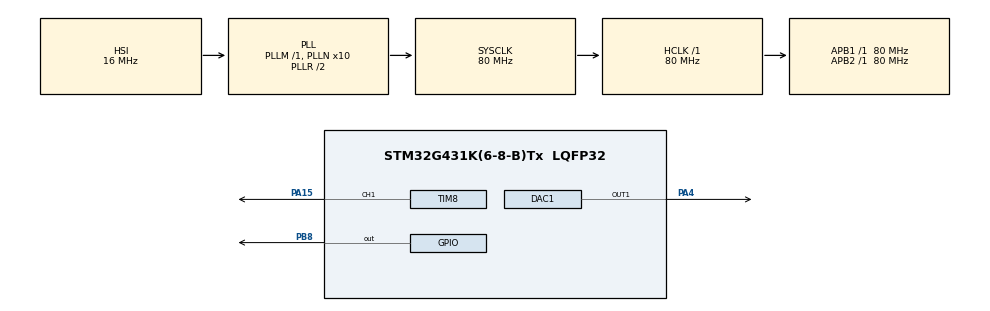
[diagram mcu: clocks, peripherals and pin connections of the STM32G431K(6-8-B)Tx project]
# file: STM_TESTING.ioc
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DAC1.DAC_SampleAndHold-DAC_OUT1=DAC_SAMPLEANDHOLD_DISABLE
DAC1.DAC_Trigger_OUT1-DAC_OUT1=DAC_TRIGGER_T2_TRGO
Dma.DAC1_CH1.0.Direction=DMA_MEMORY_TO_PERIPH
Dma.DAC1_CH1.0.EventEnable=DISABLE
Dma.DAC1_CH1.0.Instance=DMA1_Channel2
Dma.DAC1_CH1.0.MemDataAlignment=DMA_MDATAALIGN_HALFWORD
Dma.DAC1_CH1.0.MemInc=DMA_MINC_ENABLE
Dma.DAC1_CH1.0.Mode=DMA_CIRCULAR
Dma.DAC1_CH1.0.PeriphDataAlignment=DMA_PDATAALIGN_WORD
Dma.DAC1_CH1.0.PeriphInc=DMA_PINC_DISABLE
Dma.DAC1_CH1.0.Polarity=HAL_DMAMUX_REQ_GEN_RISING
Dma.DAC1_CH1.0.Priority=DMA_PRIORITY_HIGH
Dma.DAC1_CH1.0.RequestNumber=1
Dma.DAC1_CH1.0.SignalID=NONE
Dma.DAC1_CH1.0.SyncEnable=DISABLE
Dma.DAC1_CH1.0.SyncPolarity=HAL_DMAMUX_SYNC_NO_EVENT
Dma.DAC1_CH1.0.SyncRequestNumber=1
Dma.DAC1_CH1.0.SyncSignalID=NONE
Dma.Request0=DAC1_CH1
Mcu.Family=STM32G4
Mcu.Name=STM32G431K(6-8-B)Tx
Mcu.Package=LQFP32
NUCLEO-G431KB.LD2=true
NUCLEO-G431KB.VCP=true
NVIC.DMA1_Channel2_IRQn=true\:0\:0\:false\:false\:true\:false\:true\:true
NVIC.PriorityGroup=NVIC_PRIORITYGROUP_4
NVIC.TIM2_IRQn=true\:0\:0\:false\:false\:true\:true\:true\:true
NVIC.TIM8_UP_IRQn=true\:0\:0\:false\:false\:true\:true\:true\:true
PA13.GPIO_Label=T_SWDIO
PA13.Signal=SYS_JTMS-SWDIO
PA14.GPIO_Label=T_SWCLK
PA14.Signal=SYS_JTCK-SWCLK
PA15.Signal=S_TIM8_CH1
PA2.Signal=USART2_TX
PA3.Signal=USART2_RX
PA4.Signal=COMP_DAC11_group
PB3.GPIO_Label=T_SWO
PB3.Signal=SYS_JTDO-SWO
PB8-BOOT0.Signal=GPIO_Output
ProjectManager.HeapSize=0x200
ProjectManager.StackSize=0x400
ProjectManager.TargetToolchain=CMake
RCC.ADC12Freq_Value=80000000
RCC.AHBFreq_Value=80000000
RCC.APB1Freq_Value=80000000
RCC.APB1TimFreq_Value=80000000
RCC.APB2Freq_Value=80000000
RCC.APB2TimFreq_Value=80000000
RCC.CortexFreq_Value=80000000
RCC.EXTERNAL_CLOCK_VALUE=12288000
RCC.HCLKFreq_Value=80000000
RCC.HSE_VALUE=8000000
RCC.HSI48_VALUE=48000000
RCC.HSI_VALUE=16000000
RCC.LSE_VALUE=32768
RCC.PLLN=10
RCC.SYSCLKFreq_VALUE=80000000
RCC.SYSCLKSource=RCC_SYSCLKSOURCE_PLLCLK
RCC.USBFreq_Value=80000000
RCC.VCOOutputFreq_Value=160000000
SH.COMP_DAC11_group.0=DAC1_OUT1,DAC_OUT1
SH.S_TIM8_CH1.0=TIM8_CH1,PWM Generation1 CH1
TIM2.PeriodNoDither=9
TIM2.Prescaler=7999
TIM2.TIM_MasterOutputTrigger=TIM_TRGO_UPDATE
TIM8.Channel-PWM\ Generation1\ CH1=TIM_CHANNEL_1
TIM8.PeriodNoDither=9999
TIM8.Prescaler=7999
TIM8.PulseNoDither_1=10000
TIM8.RepetitionCounter=0
TIM8.TIM_MasterOutputTrigger=TIM_TRGO_OC1REF
VP_NUCLEO-G431KB_VS_BSP_COMMON.Mode=COMMON
VP_SYS_VS_DBSignals.Mode=DisableDeadBatterySignals
VP_TIM2_VS_ClockSourceINT.Mode=Internal
VP_TIM2_VS_ClockSourceITR.Mode=TriggerSource_ITR5
VP_TIM2_VS_ControllerModeGated.Mode=Gated Mode
VP_TIM8_VS_ClockSourceINT.Mode=Internal
board=NUCLEO-G431KB

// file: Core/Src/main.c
/* USER CODE BEGIN Header */
/**
 ******************************************************************************
 * @file           : main.c
 * @brief          : Main program body
 ******************************************************************************
 * @attention
 *
 * Copyright (c) 2025 STMicroelectronics.
 * All rights reserved.
 *
 * This software is licensed under terms that can be found in the LICENSE file
 * in the root directory of this software component.
 * If no LICENSE file comes with this software, it is provided AS-IS.
 *
 ******************************************************************************
 */
/* USER CODE END Header */
#include "main.h"

/* USER CODE BEGIN Includes */

#include <math.h>
#include <stdint.h>

/* USER CODE END Includes */

/* USER CODE BEGIN PD */

#define pi 3.14159265358979323846
#define MAX_SAMPLES_21k 48
#define MAX_SAMPLES_22k 45
#define BITSTREAM_LENGTH (32 * 8)

#define NUM_PERIODS_21k 30
#define NUM_PERIODS_22k 32

/* USER CODE END PD */

COM_InitTypeDef BspCOMInit;

DAC_HandleTypeDef hdac1;
DMA_HandleTypeDef hdma_dac1_ch1;

TIM_HandleTypeDef htim2;
TIM_HandleTypeDef htim8;

/* USER CODE BEGIN PV */

uint16_t sine_val_21k[MAX_SAMPLES_21k];
uint16_t sine_val_22k[MAX_SAMPLES_22k];

uint16_t bitstream[BITSTREAM_LENGTH];

static uint32_t current_period = 0;
static uint32_t current_bit = 0; // 0: 21kHz, 1: 22kHz
static uint32_t current_idx = 0; // Current index of the bitstream

/* USER CODE END PV */

void SystemClock_Config(void);
static void MX_GPIO_Init(void);
static void MX_DMA_Init(void);
static void MX_TIM2_Init(void);
static void MX_DAC1_Init(void);
static void MX_TIM8_Init(void);

/* USER CODE BEGIN 0 */

void make_random_bitstream(void) {
  for (int i = 0; i < BITSTREAM_LENGTH; i++) {
    bitstream[i] = rand() & 1; // Random bit (0 or 1)
  }
}

void make_bitstream_from_string(const char *str) {
  int bit_idx = 0;
  for (int i = 0; str[i] != '\0' && bit_idx < BITSTREAM_LENGTH; i++) {
    for (int b = 0; b < 8 && bit_idx < BITSTREAM_LENGTH; b++) {
      bitstream[bit_idx++] = (str[i] >> b) & 1;
    }
  }
  // Fill remaining bits with 0 if string is shorter than BITSTREAM_LENGTH
  while (bit_idx < BITSTREAM_LENGTH) {
    bitstream[bit_idx++] = 0;
  }
}

void get_sineval_21k(void) {
  for (int i = 0; i < MAX_SAMPLES_21k; i++) {
    sine_val_21k[i] = (uint16_t)((4095.0 / 2.0) *
                                 (1.0 + sinf(2.0 * pi * i / MAX_SAMPLES_21k)));
  }
}

void get_sineval_22k(void) {
  for (int i = 0; i < MAX_SAMPLES_22k; i++) {
    sine_val_22k[i] = (uint16_t)((4095.0 / 2.0) *
                                 (1.0 + sinf(2.0 * pi * i / MAX_SAMPLES_22k)));
  }
}

void HAL_TIM_PeriodElapsedCallback(TIM_HandleTypeDef *htim) {
  if (htim->Instance == TIM8) {
  }

  if (htim->Instance == TIM2) {
  }
}

void HAL_DAC_ConvCpltCallbackCh1(DAC_HandleTypeDef *hdac) {
  HAL_GPIO_TogglePin(GPIOA, GPIO_PIN_5);

  current_period++;

  if ((current_bit == 0 && current_period >= NUM_PERIODS_21k) ||
      (current_bit == 1 && current_period >= NUM_PERIODS_22k)) {
    current_idx = (current_idx + 1) % BITSTREAM_LENGTH;
    current_period = 0;
    uint32_t next_bit = bitstream[current_idx];

    if (next_bit != current_bit) {
      HAL_DAC_Stop_DMA(&hdac1, DAC_CHANNEL_1);

      if (next_bit == 1) {
        HAL_DAC_Start_DMA(&hdac1, DAC_CHANNEL_1, (uint32_t *)sine_val_22k,
                          MAX_SAMPLES_22k, DAC_ALIGN_12B_R);
      } else {
        HAL_DAC_Start_DMA(&hdac1, DAC_CHANNEL_1, (uint32_t *)sine_val_21k,
                          MAX_SAMPLES_21k, DAC_ALIGN_12B_R);
      }
      current_bit = next_bit;
    }
  }
}

void HAL_DAC_ConvHalfCpltCallbackCh1(DAC_HandleTypeDef *hdac) {
  // Called halfway through buffer
}

/* USER CODE END 0 */

int main(void) {

  /* MCU Configuration--------------------------------------------------------*/

  /* Reset of all peripherals, Initializes the Flash interface and the Systick.
   */
  HAL_Init();

  /* Configure the system clock */
  SystemClock_Config();

  /* Initialize all configured peripherals */
  MX_GPIO_Init();
  MX_DMA_Init();
  MX_TIM2_Init();
  MX_DAC1_Init();
  MX_TIM8_Init();

  /* Initialize leds */
  BSP_LED_Init(LED_GREEN);

  /* Initialize COM1 port (115200, 8 bits (7-bit data + 1 stop bit), no parity
   */
  BspCOMInit.BaudRate = 115200;
  BspCOMInit.WordLength = COM_WORDLENGTH_8B;
  BspCOMInit.StopBits = COM_STOPBITS_1;
  BspCOMInit.Parity = COM_PARITY_NONE;
  BspCOMInit.HwFlowCtl = COM_HWCONTROL_NONE;
  if (BSP_COM_Init(COM1, &BspCOMInit) != BSP_ERROR_NONE) {
    Error_Handler();
  }

  /* Infinite loop */
  /* USER CODE BEGIN WHILE */

  //-------------------------------------------------------------------------------------------//
  // Create a bistream from a string
  //-------------------------------------------------------------------------------------------//

  const char *input_string = "Hello"; // Example input string
  make_bitstream_from_string(input_string);
  // make_random_bitstream(); // or fill bitstream[] your way

  //-------------------------------------------------------------------------------------------//
  // Generate the sine wave lookup table
  //-------------------------------------------------------------------------------------------//

  get_sineval_21k();
  get_sineval_22k();

  //-------------------------------------------------------------------------------------------//
  // Generate the sine wave lookup table
  //-------------------------------------------------------------------------------------------//

  HAL_DAC_Start_DMA(&hdac1, DAC_CHANNEL_1, (uint32_t *)sine_val_21k,
                    MAX_SAMPLES_21k, DAC_ALIGN_12B_R);

  //-------------------------------------------------------------------------------------------//
  // STARTING TIMERS AND INTERRUPTS
  //-------------------------------------------------------------------------------------------//

  HAL_TIM_Base_Start_IT(&htim8); // enable update interrupt
  HAL_TIM_PWM_Start(&htim8, TIM_CHANNEL_1);

  // Start TIM2 (sample clock, gated by TIM8)
  HAL_TIM_Base_Start_IT(&htim2);

  //-------------------------------------------------------------------------------------------//

  while (1) {
    /* USER CODE END WHILE */

  }
}

void SystemClock_Config(void) {
  RCC_OscInitTypeDef RCC_OscInitStruct = {0};
  RCC_ClkInitTypeDef RCC_ClkInitStruct = {0};

  /** Configure the main internal regulator output voltage
   */
  HAL_PWREx_ControlVoltageScaling(PWR_REGULATOR_VOLTAGE_SCALE1);

  /** Initializes the RCC Oscillators according to the specified parameters
   * in the RCC_OscInitTypeDef structure.
   */
  RCC_OscInitStruct.OscillatorType = RCC_OSCILLATORTYPE_HSI;
  RCC_OscInitStruct.HSIState = RCC_HSI_ON;
  RCC_OscInitStruct.HSICalibrationValue = RCC_HSICALIBRATION_DEFAULT;
  RCC_OscInitStruct.PLL.PLLState = RCC_PLL_ON;
  RCC_OscInitStruct.PLL.PLLSource = RCC_PLLSOURCE_HSI;
  RCC_OscInitStruct.PLL.PLLM = RCC_PLLM_DIV1;
  RCC_OscInitStruct.PLL.PLLN = 10;
  RCC_OscInitStruct.PLL.PLLP = RCC_PLLP_DIV2;
  RCC_OscInitStruct.PLL.PLLQ = RCC_PLLQ_DIV2;
  RCC_OscInitStruct.PLL.PLLR = RCC_PLLR_DIV2;
  if (HAL_RCC_OscConfig(&RCC_OscInitStruct) != HAL_OK) {
    Error_Handler();
  }

  /** Initializes the CPU, AHB and APB buses clocks
   */
  RCC_ClkInitStruct.ClockType = RCC_CLOCKTYPE_HCLK | RCC_CLOCKTYPE_SYSCLK |
                                RCC_CLOCKTYPE_PCLK1 | RCC_CLOCKTYPE_PCLK2;
  RCC_ClkInitStruct.SYSCLKSource = RCC_SYSCLKSOURCE_PLLCLK;
  RCC_ClkInitStruct.AHBCLKDivider = RCC_SYSCLK_DIV1;
  RCC_ClkInitStruct.APB1CLKDivider = RCC_HCLK_DIV1;
  RCC_ClkInitStruct.APB2CLKDivider = RCC_HCLK_DIV1;

  if (HAL_RCC_ClockConfig(&RCC_ClkInitStruct, FLASH_LATENCY_2) != HAL_OK) {
    Error_Handler();
  }
}

static void MX_DAC1_Init(void) {

  DAC_ChannelConfTypeDef sConfig = {0};

  /** DAC Initialization
   */
  hdac1.Instance = DAC1;
  if (HAL_DAC_Init(&hdac1) != HAL_OK) {
    Error_Handler();
  }

  /** DAC channel OUT1 config
   */
  sConfig.DAC_HighFrequency = DAC_HIGH_FREQUENCY_INTERFACE_MODE_AUTOMATIC;
  sConfig.DAC_DMADoubleDataMode = DISABLE;
  sConfig.DAC_SignedFormat = DISABLE;
  sConfig.DAC_SampleAndHold = DAC_SAMPLEANDHOLD_DISABLE;
  sConfig.DAC_Trigger = DAC_TRIGGER_T2_TRGO;
  sConfig.DAC_Trigger2 = DAC_TRIGGER_NONE;
  sConfig.DAC_OutputBuffer = DAC_OUTPUTBUFFER_ENABLE;
  sConfig.DAC_ConnectOnChipPeripheral = DAC_CHIPCONNECT_EXTERNAL;
  sConfig.DAC_UserTrimming = DAC_TRIMMING_FACTORY;
  if (HAL_DAC_ConfigChannel(&hdac1, &sConfig, DAC_CHANNEL_1) != HAL_OK) {
    Error_Handler();
  }
}

static void MX_TIM2_Init(void) {

  TIM_ClockConfigTypeDef sClockSourceConfig = {0};
  TIM_SlaveConfigTypeDef sSlaveConfig = {0};
  TIM_MasterConfigTypeDef sMasterConfig = {0};

  htim2.Instance = TIM2;
  htim2.Init.Prescaler = 0;
  htim2.Init.CounterMode = TIM_COUNTERMODE_UP;
  htim2.Init.Period = 79;
  htim2.Init.ClockDivision = TIM_CLOCKDIVISION_DIV1;
  htim2.Init.AutoReloadPreload = TIM_AUTORELOAD_PRELOAD_DISABLE;
  if (HAL_TIM_Base_Init(&htim2) != HAL_OK) {
    Error_Handler();
  }
  sClockSourceConfig.ClockSource = TIM_CLOCKSOURCE_INTERNAL;
  if (HAL_TIM_ConfigClockSource(&htim2, &sClockSourceConfig) != HAL_OK) {
    Error_Handler();
  }
  sSlaveConfig.SlaveMode = TIM_SLAVEMODE_GATED;
  sSlaveConfig.InputTrigger = TIM_TS_ITR5;
  if (HAL_TIM_SlaveConfigSynchro(&htim2, &sSlaveConfig) != HAL_OK) {
    Error_Handler();
  }
  sMasterConfig.MasterOutputTrigger = TIM_TRGO_UPDATE;
  sMasterConfig.MasterSlaveMode = TIM_MASTERSLAVEMODE_DISABLE;
  if (HAL_TIMEx_MasterConfigSynchronization(&htim2, &sMasterConfig) != HAL_OK) {
    Error_Handler();
  }
}

static void MX_TIM8_Init(void) {

  TIM_ClockConfigTypeDef sClockSourceConfig = {0};
  TIM_MasterConfigTypeDef sMasterConfig = {0};
  TIM_OC_InitTypeDef sConfigOC = {0};
  TIM_BreakDeadTimeConfigTypeDef sBreakDeadTimeConfig = {0};

  htim8.Instance = TIM8;
  htim8.Init.Prescaler = 7999;
  htim8.Init.CounterMode = TIM_COUNTERMODE_UP;
  htim8.Init.Period = 9999;
  htim8.Init.ClockDivision = TIM_CLOCKDIVISION_DIV1;
  htim8.Init.RepetitionCounter = 0;
  htim8.Init.AutoReloadPreload = TIM_AUTORELOAD_PRELOAD_DISABLE;
  if (HAL_TIM_Base_Init(&htim8) != HAL_OK) {
    Error_Handler();
  }
  sClockSourceConfig.ClockSource = TIM_CLOCKSOURCE_INTERNAL;
  if (HAL_TIM_ConfigClockSource(&htim8, &sClockSourceConfig) != HAL_OK) {
    Error_Handler();
  }
  if (HAL_TIM_PWM_Init(&htim8) != HAL_OK) {
    Error_Handler();
  }
  sMasterConfig.MasterOutputTrigger = TIM_TRGO_OC1REF;
  sMasterConfig.MasterOutputTrigger2 = TIM_TRGO2_RESET;
  sMasterConfig.MasterSlaveMode = TIM_MASTERSLAVEMODE_DISABLE;
  if (HAL_TIMEx_MasterConfigSynchronization(&htim8, &sMasterConfig) != HAL_OK) {
    Error_Handler();
  }
  sConfigOC.OCMode = TIM_OCMODE_PWM1;
  sConfigOC.Pulse = 10000;
  sConfigOC.OCPolarity = TIM_OCPOLARITY_HIGH;
  sConfigOC.OCNPolarity = TIM_OCNPOLARITY_HIGH;
  sConfigOC.OCFastMode = TIM_OCFAST_DISABLE;
  sConfigOC.OCIdleState = TIM_OCIDLESTATE_RESET;
  sConfigOC.OCNIdleState = TIM_OCNIDLESTATE_RESET;
  if (HAL_TIM_PWM_ConfigChannel(&htim8, &sConfigOC, TIM_CHANNEL_1) != HAL_OK) {
    Error_Handler();
  }
  sBreakDeadTimeConfig.OffStateRunMode = TIM_OSSR_DISABLE;
  sBreakDeadTimeConfig.OffStateIDLEMode = TIM_OSSI_DISABLE;
  sBreakDeadTimeConfig.LockLevel = TIM_LOCKLEVEL_OFF;
  sBreakDeadTimeConfig.DeadTime = 0;
  sBreakDeadTimeConfig.BreakState = TIM_BREAK_DISABLE;
  sBreakDeadTimeConfig.BreakPolarity = TIM_BREAKPOLARITY_HIGH;
  sBreakDeadTimeConfig.BreakFilter = 0;
  sBreakDeadTimeConfig.BreakAFMode = TIM_BREAK_AFMODE_INPUT;
  sBreakDeadTimeConfig.Break2State = TIM_BREAK2_DISABLE;
  sBreakDeadTimeConfig.Break2Polarity = TIM_BREAK2POLARITY_HIGH;
  sBreakDeadTimeConfig.Break2Filter = 0;
  sBreakDeadTimeConfig.Break2AFMode = TIM_BREAK_AFMODE_INPUT;
  sBreakDeadTimeConfig.AutomaticOutput = TIM_AUTOMATICOUTPUT_DISABLE;
  if (HAL_TIMEx_ConfigBreakDeadTime(&htim8, &sBreakDeadTimeConfig) != HAL_OK) {
    Error_Handler();
  }
  HAL_TIM_MspPostInit(&htim8);
}

static void MX_DMA_Init(void) {

  /* DMA controller clock enable */
  __HAL_RCC_DMAMUX1_CLK_ENABLE();
  __HAL_RCC_DMA1_CLK_ENABLE();

  /* DMA interrupt init */
  /* DMA1_Channel2_IRQn interrupt configuration */
  HAL_NVIC_SetPriority(DMA1_Channel2_IRQn, 0, 0);
  HAL_NVIC_EnableIRQ(DMA1_Channel2_IRQn);
}

static void MX_GPIO_Init(void) {

  /* GPIO Ports Clock Enable */
  __HAL_RCC_GPIOA_CLK_ENABLE();
  __HAL_RCC_GPIOB_CLK_ENABLE();

}

/* USER CODE BEGIN Header */
/**
 ******************************************************************************
 * @file           : main.c
 * @brief          : Main program body
 ******************************************************************************
 * @attention
 *
 * Copyright (c) 2025 STMicroelectronics.
 * All rights reserved.
 *
 * This software is licensed under terms that can be found in the LICENSE file
 * in the root directory of this software component.
 * If no LICENSE file comes with this software, it is provided AS-IS.
 *
 ******************************************************************************
 */
/* USER CODE END Header */

void Error_Handler(void) {
  /* USER CODE BEGIN Error_Handler_Debug */
  /* User can add his own implementation to report the HAL error return
   * state */
  __disable_irq();
  while (1) {
  }
  /* USER CODE END Error_Handler_Debug */
}
#ifdef USE_FULL_ASSERT
/**
 * @brief  Reports the name of the source file and the source line number
 *         where the assert_param error has occurred.
 * @param  file: pointer to the source file name
 * @param  line: assert_param error line source number
 * @retval None
 */
void assert_failed(uint8_t *file, uint32_t line) {
  /* USER CODE BEGIN 6 */
  /* User can add his own implementation to report the file name and line
     number, ex: printf("Wrong parameters value: file %s on line %d\r\n",
     file, line) */
  /* USER CODE END 6 */
}
#endif /* USE_FULL_ASSERT */
